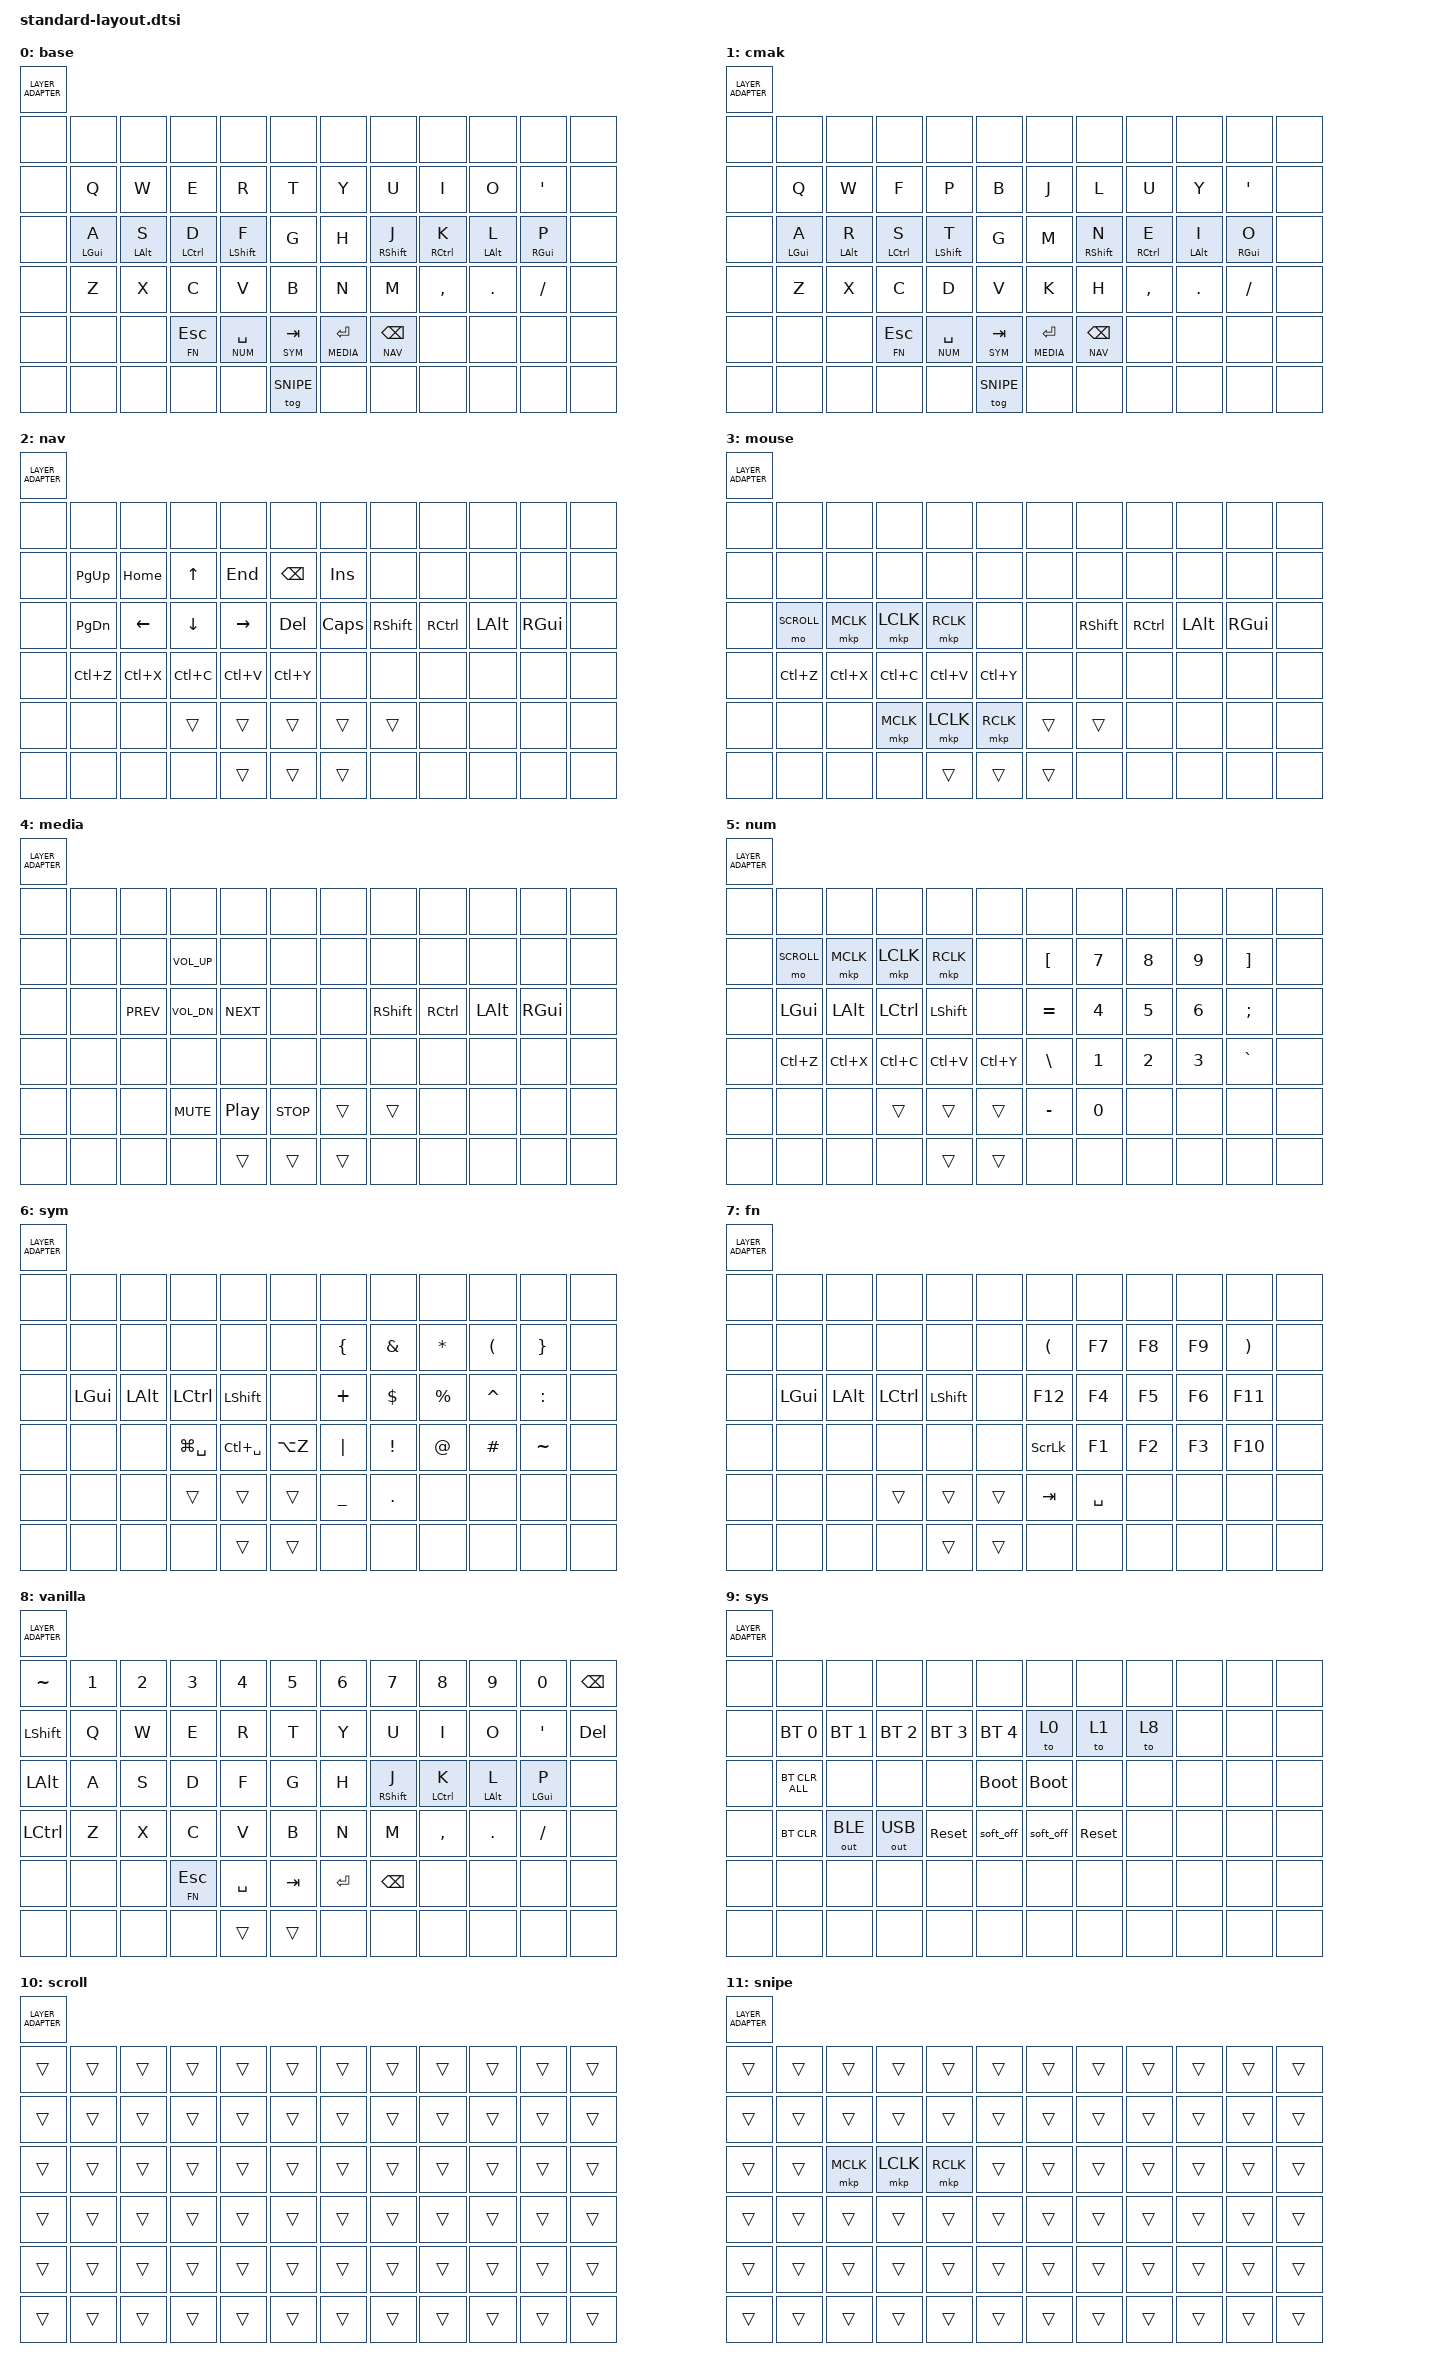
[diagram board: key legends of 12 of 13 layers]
#include <behaviors.dtsi>
#include <dt-bindings/zmk/bt.h>
#include <dt-bindings/zmk/outputs.h>
#include <dt-bindings/zmk/ext_power.h>
#include <dt-bindings/zmk/keys.h>

#define BASE    0
#define CMAK    1
#define NAV     2
#define MOUSE   3
#define MEDIA   4
#define NUM     5
#define SYM     6
#define FN      7
#define VANILLA 8
#define SYS     9
#define SCROLL  10
#define SNIPE   11
#define AUTOM   12
#define XXX     &none
#define ___     &trans

&lt {
    quick-tap-ms = <200>;
};

&caps_word {
    continue-list = <UNDERSCORE MINUS BSPC>;
};

/ {
    conditional_layers {
        compatible = "zmk,conditional-layers";
        tri_layer_right {
            if-layers = <MEDIA NAV>;
            then-layer = <SYS>;
        };
        tri_layer_left {
            if-layers = <SYM NUM>;
            then-layer = <SYS>;
        };
        tri_layer_scroll {
            if-layers = <NUM FN>;
            then-layer = <SCROLL>;
        };
    };
};

/ {
    behaviors {
        hm: homerow_mods {
            compatible = "zmk,behavior-hold-tap";
            #binding-cells = <2>;
            flavor = "tap-preferred";
            tapping-term-ms = <200>;
            quick-tap-ms = <200>;
            bindings = <&kp>, <&kp>;
        };
        mlt: mouse_layer_tap {
            compatible = "zmk,behavior-hold-tap";
            #binding-cells = <2>;
            tapping-term-ms = <200>;
            quick-tap-ms = <200>;
            flavor = "tap-preferred";
            bindings = <&mo>, <&mkp>;
        };
        lpar_ht: lpar_hold_tap {
            compatible = "zmk,behavior-hold-tap";
            #binding-cells = <2>;
            flavor = "tap-preferred";
            tapping-term-ms = <200>;
            quick-tap-ms = <200>;
            bindings = <&lpar_hold_macro>, <&kp>;
        };
        rpar_ht: rpar_hold_tap {
            compatible = "zmk,behavior-hold-tap";
            #binding-cells = <2>;
            flavor = "tap-preferred";
            tapping-term-ms = <200>;
            quick-tap-ms = <200>;
            bindings = <&rpar_hold_macro>, <&kp>;
        };
        lpar_hold_macro: lpar_hold_macro {
            compatible = "zmk,behavior-macro";
            #binding-cells = <0>;
            bindings = <&macro_press &kp LSHFT &kp LCTRL>,
                        <&macro_pause_for_release>,
                        <&macro_release &kp LSHFT &kp LCTRL>;
        };
        rpar_hold_macro: rpar_hold_macro {
            compatible = "zmk,behavior-macro";
            #binding-cells = <0>;
            bindings = <&macro_press &kp LCTRL &kp LALT>,
                        <&macro_pause_for_release>,
                        <&macro_release &kp LCTRL &kp LALT>;
        };
        tog_sys: toggle_sys_macro {
            compatible = "zmk,behavior-macro";
            #binding-cells = <0>;
            bindings = <&kp S &kp Y &kp S &kp SPACE &kp L &kp A &kp Y &kp E &kp R>,
                        <&tog SYS>;
        };
    };
};

/ {
    combos {
        compatible = "zmk,combos";
        combo_caps_word {
            timeout-ms = <50>;
            require-prior-idle-ms = <150>;
            key-positions = <LM1 RM1>;
            bindings = <&caps_word>;
        };
        combo_bspc {
            timeout-ms = <50>;
            require-prior-idle-ms = <150>;
            layers = <BASE CMAK>;
            key-positions = <RT1 RT2>;
            bindings = <&kp BSPC>;
        };
        combo_del {
            timeout-ms = <50>;
            require-prior-idle-ms = <150>;
            layers = <BASE CMAK>;
            key-positions = <RT2 RT3>;
            bindings = <&kp DEL>;
        };
        combo_lpar {
            timeout-ms = <50>;
            require-prior-idle-ms = <150>;
            layers = <BASE CMAK>;
            key-positions = <RM1 RM2>;
            bindings = <&lpar_ht 0 LPAR>;
        };
        combo_rpar {
            timeout-ms = <50>;
            require-prior-idle-ms = <150>;
            layers = <BASE CMAK>;
            key-positions = <RM2 RM3>;
            bindings = <&rpar_ht 0 RPAR>;
        };
        combo_lessthan {
            timeout-ms = <50>;
            require-prior-idle-ms = <150>;
            layers = <NUM>;
            key-positions = <RM1 RM2>;
            bindings = <&kp LT>;
        };
        combo_greaterthan {
            timeout-ms = <50>;
            require-prior-idle-ms = <150>;
            layers = <NUM>;
            key-positions = <RM2 RM3>;
            bindings = <&kp GT>;
        };
        combo_lbkt {
            timeout-ms = <50>;
            require-prior-idle-ms = <150>;
            layers = <BASE CMAK>;
            key-positions = <RB1 RB2>;
            bindings = <&kp LBKT>;
        };
        combo_rbkt {
            timeout-ms = <50>;
            require-prior-idle-ms = <150>;
            layers = <BASE CMAK>;
            key-positions = <RB2 RB3>;
            bindings = <&kp RBKT>;
        };
        combo_lbrc {
            timeout-ms = <50>;
            require-prior-idle-ms = <150>;
            layers = <NUM>;
            key-positions = <RB1 RB2>;
            bindings = <&kp LBRC>;
        };
        combo_rbrc {
            timeout-ms = <50>;
            require-prior-idle-ms = <150>;
            layers = <NUM>;
            key-positions = <RB2 RB3>;
            bindings = <&kp RBRC>;
        };
    };
};

// Keyboard Layout definition
// -----------------------------------------------------------------------------
// Not all keys defined here are used in all keyboards this layout suppots. To
// check where a key defined here is located on the physical layout of a
// keyboard, look in the keyboard's '.keymap' file.
/ {
    keymap {
        compatible = "zmk,keymap";

        base {
            bindings = <LAYER_ADAPTER(
XXX,            XXX,            XXX,            XXX,            XXX,            XXX,                    XXX,            XXX,            XXX,            XXX,            XXX,            XXX,
XXX,            &kp Q,          &kp W,          &kp E,          &kp R,          &kp T,                  &kp Y,          &kp U,          &kp I,          &kp O,          &kp SQT,        XXX,
XXX,            &hm LGUI A,     &hm LALT S,     &hm LCTRL D,    &hm LSHFT F,    &kp G,                  &kp H,          &hm RSHFT J,    &hm RCTRL K,    &hm LALT L,     &hm RGUI P,     XXX,
XXX,            &kp Z,          &kp X,          &kp C,          &kp V,          &kp B,                  &kp N,          &kp M,          &kp COMMA,      &kp DOT,        &kp FSLH,       XXX,
XXX,            XXX,            XXX,            &lt FN ESC,     &lt NUM SPACE,  &lt SYM TAB,            &lt MEDIA RET,  &lt NAV BSPC,   XXX,            XXX,            XXX,            XXX,
XXX,            XXX,            XXX,            XXX,            XXX,            &tog SNIPE,             XXX,            XXX,            XXX,            XXX,            XXX,            XXX
            )>;
        };

        cmak {
            bindings = <LAYER_ADAPTER(
XXX,            XXX,            XXX,            XXX,            XXX,            XXX,                    XXX,            XXX,            XXX,            XXX,            XXX,            XXX,
XXX,            &kp Q,          &kp W,          &kp F,          &kp P,          &kp B,                  &kp J,          &kp L,          &kp U,          &kp Y,          &kp SQT,        XXX,
XXX,            &hm LGUI A,     &hm LALT R,     &hm LCTRL S,    &hm LSHFT T,    &kp G,                  &kp M,          &hm RSHFT N,    &hm RCTRL E,    &hm LALT I,     &hm RGUI O,     XXX,
XXX,            &kp Z,          &kp X,          &kp C,          &kp D,          &kp V,                  &kp K,          &kp H,          &kp COMMA,      &kp DOT,        &kp FSLH,       XXX,
XXX,            XXX,            XXX,            &lt FN ESC,     &lt NUM SPACE,  &lt SYM TAB,            &lt MEDIA RET,  &lt NAV BSPC,   XXX,            XXX,            XXX,            XXX,
XXX,            XXX,            XXX,            XXX,            XXX,            &tog SNIPE,             XXX,            XXX,            XXX,            XXX,            XXX,            XXX
            )>;
        };

        nav {
            bindings = <LAYER_ADAPTER(
XXX,            XXX,            XXX,            XXX,            XXX,            XXX,                    XXX,            XXX,            XXX,            XXX,            XXX,            XXX,
XXX,            &kp PG_UP,      &kp HOME,       &kp UP,         &kp END,        &kp BSPC,               &kp INS,        XXX,            XXX,            XXX,            XXX,            XXX,
XXX,            &kp PG_DN,      &kp LEFT,       &kp DOWN,       &kp RIGHT,      &kp DEL,                &kp CAPS,       &kp RSHFT,      &kp RCTRL,      &kp LALT,       &kp RGUI,       XXX,
XXX,            &kp LC(Z),      &kp LC(X),      &kp LC(C),      &kp LC(V),      &kp LC(Y),              XXX,            XXX,            XXX,            XXX,            XXX,            XXX,
XXX,            XXX,            XXX,            ___,            ___,            ___,                    ___,            ___,            XXX,            XXX,            XXX,            XXX,
XXX,            XXX,            XXX,            XXX,            ___,            ___,                    ___,            XXX,            XXX,            XXX,            XXX,            XXX
            )>;
        };

        mouse {
            bindings = <LAYER_ADAPTER(
XXX,            XXX,            XXX,            XXX,            XXX,            XXX,                    XXX,            XXX,            XXX,            XXX,            XXX,            XXX,
XXX,            XXX,            XXX,            XXX,            XXX,            XXX,                    XXX,            XXX,            XXX,            XXX,            XXX,            XXX,
XXX,            &mo SCROLL,     &mkp MCLK,      &mkp LCLK,      &mkp RCLK,      XXX,                    XXX,            &kp RSHFT,      &kp RCTRL,      &kp LALT,       &kp RGUI,       XXX,
XXX,            &kp LC(Z),      &kp LC(X),      &kp LC(C),      &kp LC(V),      &kp LC(Y),              XXX,            XXX,            XXX,            XXX,            XXX,            XXX,
XXX,            XXX,            XXX,            &mkp MCLK,      &mkp LCLK,      &mkp RCLK,              ___,            ___,            XXX,            XXX,            XXX,            XXX,
XXX,            XXX,            XXX,            XXX,            ___,            ___,                    ___,            XXX,            XXX,            XXX,            XXX,            XXX
            )>;
        };

        media {
            bindings = <LAYER_ADAPTER(
XXX,            XXX,            XXX,            XXX,            XXX,            XXX,                    XXX,            XXX,            XXX,            XXX,            XXX,            XXX,
XXX,            XXX,            XXX,            &kp C_VOL_UP,   XXX,            XXX,                    XXX,            XXX,            XXX,            XXX,            XXX,            XXX,
XXX,            XXX,            &kp C_PREV,     &kp C_VOL_DN,   &kp C_NEXT,     XXX,                    XXX,            &kp RSHFT,      &kp RCTRL,      &kp LALT,       &kp RGUI,       XXX,
XXX,            XXX,            XXX,            XXX,            XXX,            XXX,                    XXX,            XXX,            XXX,            XXX,            XXX,            XXX,
XXX,            XXX,            XXX,            &kp C_MUTE,     &kp C_PP,       &kp C_STOP,             ___,            ___,            XXX,            XXX,            XXX,            XXX,
XXX,            XXX,            XXX,            XXX,            ___,            ___,                    ___,            XXX,            XXX,            XXX,            XXX,            XXX
            )>;
        };

        num {
            bindings = <LAYER_ADAPTER(
XXX,            XXX,            XXX,            XXX,            XXX,            XXX,                    XXX,           XXX,            XXX,            XXX,            XXX,           XXX,
XXX,            &mo SCROLL,     &mkp MCLK,      &mkp LCLK,      &mkp RCLK,      XXX,                    &kp LBKT,      &kp N7,         &kp N8,         &kp N9,         &kp RBKT,      XXX,
XXX,            &kp LGUI,       &kp LALT,       &kp LCTRL,      &kp LSHFT,      XXX,                    &kp EQUAL,     &kp N4,         &kp N5,         &kp N6,         &kp SEMI,      XXX,
XXX,            &kp LC(Z),      &kp LC(X),      &kp LC(C),      &kp LC(V),      &kp LC(Y),              &kp BSLH,      &kp N1,         &kp N2,         &kp N3,         &kp GRAVE,     XXX,
XXX,            XXX,            XXX,            ___,            ___,            ___,                    &kp MINUS,     &kp N0,         XXX,            XXX,            XXX,           XXX,
XXX,            XXX,            XXX,            XXX,            ___,            ___,                    XXX,           XXX,            XXX,            XXX,            XXX,           XXX
            )>;
        };

        sym {
            bindings = <LAYER_ADAPTER(
XXX,            XXX,            XXX,            XXX,            XXX,            XXX,                    XXX,            XXX,            XXX,            XXX,            XXX,            XXX,
XXX,            XXX,            XXX,            XXX,            XXX,            XXX,                    &kp LBRC,       &kp AMPS,       &kp ASTRK,      &kp LPAR,       &kp RBRC,       XXX,
XXX,            &kp LGUI,       &kp LALT,       &kp LCTRL,      &kp LSHFT,      XXX,                    &kp PLUS,       &kp DLLR,       &kp PRCNT,      &kp CARET,      &kp COLON,      XXX,
XXX,            XXX,            XXX,            &kp LG(SPACE),  &kp LC(SPACE),  &kp LA(Z),              &kp PIPE,       &kp EXCL,       &kp AT,         &kp HASH,       &kp TILDE,      XXX,
XXX,            XXX,            XXX,            ___,            ___,            ___,                    &kp UNDER,      &kp DOT,        XXX,            XXX,            XXX,            XXX,
XXX,            XXX,            XXX,            XXX,            ___,            ___,                    XXX,            XXX,            XXX,            XXX,            XXX,            XXX
            )>;
        };

        fn {
            bindings = <LAYER_ADAPTER(
XXX,             XXX,            XXX,            XXX,            XXX,           XXX,                    XXX,            XXX,            XXX,            XXX,            XXX,            XXX,
XXX,             XXX,            XXX,            XXX,            XXX,           XXX,                    &kp LPAR,       &kp F7,         &kp F8,         &kp F9,         &kp RPAR,       XXX,
XXX,             &kp LGUI,       &kp LALT,       &kp LCTRL,      &kp LSHFT,     XXX,                    &kp F12,        &kp F4,         &kp F5,         &kp F6,         &kp F11,        XXX,
XXX,             XXX,            XXX,            XXX,            XXX,           XXX,                    &kp SLCK,       &kp F1,         &kp F2,         &kp F3,         &kp F10,        XXX,
XXX,             XXX,            XXX,            ___,            ___,           ___,                    &kp TAB,        &kp SPACE,      XXX,            XXX,            XXX,            XXX,
XXX,             XXX,            XXX,            XXX,            ___,           ___,                    XXX,            XXX,            XXX,            XXX,            XXX,            XXX
            )>;
        };

        vanilla {
            bindings = <LAYER_ADAPTER(
&kp TILDE,      &kp 1,          &kp 2,          &kp 3,          &kp 4,          &kp 5,                  &kp 6,          &kp 7,          &kp 8,          &kp 9,          &kp 0,          &kp BSPC,
&kp LSHFT,      &kp Q,          &kp W,          &kp E,          &kp R,          &kp T,                  &kp Y,          &kp U,          &kp I,          &kp O,          &kp SQT,        &kp DEL,
&kp LALT,       &kp A,          &kp S,          &kp D,          &kp F,          &kp G,                  &kp H,          &hm RSHIFT J,   &hm LCTRL K,    &hm LALT L,     &hm LGUI P,     XXX,
&kp LCTRL,      &kp Z,          &kp X,          &kp C,          &kp V,          &kp B,                  &kp N,          &kp M,          &kp COMMA,      &kp DOT,        &kp FSLH,       XXX,
XXX,            XXX,            XXX,            &lt FN ESC,     &kp SPACE,      &kp TAB,                &kp RET,        &kp BSPC,       XXX,            XXX,            XXX,            XXX,
XXX,            XXX,            XXX,            XXX,            ___,            ___,                    XXX,            XXX,            XXX,            XXX,            XXX,            XXX
            )>;
        };

        sys {
            bindings = <LAYER_ADAPTER(
XXX,            XXX,            XXX,            XXX,            XXX,            XXX,                    XXX,            XXX,            XXX,            XXX,            XXX,            XXX,
XXX,            &bt BT_SEL 0,   &bt BT_SEL 1,   &bt BT_SEL 2,   &bt BT_SEL 3,   &bt BT_SEL 4,           &to 0,          &to 1,          &to 8,          XXX,            XXX,            XXX,
XXX,            &bt BT_CLR_ALL, XXX,            XXX,            XXX,            &bootloader,            &bootloader,    XXX,            XXX,            XXX,            XXX,            XXX,
XXX,            &bt BT_CLR,     &out OUT_BLE,   &out OUT_USB,   &sys_reset,     &soft_off,              &soft_off,      &sys_reset,     XXX,            XXX,            XXX,            XXX,
XXX,            XXX,            XXX,            XXX,            XXX,            XXX,                    XXX,            XXX,            XXX,            XXX,            XXX,            XXX,
XXX,            XXX,            XXX,            XXX,            XXX,            XXX,                    XXX,            XXX,            XXX,            XXX,            XXX,            XXX
            )>;
        };

        scroll {
            bindings = <LAYER_ADAPTER(
___,            ___,            ___,            ___,            ___,            ___,                    ___,            ___,            ___,            ___,            ___,            ___,
___,            ___,            ___,            ___,            ___,            ___,                    ___,            ___,            ___,            ___,            ___,            ___,
___,            ___,            ___,            ___,            ___,            ___,                    ___,            ___,            ___,            ___,            ___,            ___,
___,            ___,            ___,            ___,            ___,            ___,                    ___,            ___,            ___,            ___,            ___,            ___,
___,            ___,            ___,            ___,            ___,            ___,                    ___,            ___,            ___,            ___,            ___,            ___,
___,            ___,            ___,            ___,            ___,            ___,                    ___,            ___,            ___,            ___,            ___,            ___
            )>;
        };

        snipe {
            bindings = <LAYER_ADAPTER(
___,            ___,            ___,            ___,            ___,            ___,                    ___,            ___,            ___,            ___,            ___,            ___,
___,            ___,            ___,            ___,            ___,            ___,                    ___,            ___,            ___,            ___,            ___,            ___,
___,            ___,            &mkp MCLK,      &mkp LCLK,      &mkp RCLK,      ___,                    ___,            ___,            ___,            ___,            ___,            ___,
___,            ___,            ___,            ___,            ___,            ___,                    ___,            ___,            ___,            ___,            ___,            ___,
___,            ___,            ___,            ___,            ___,            ___,                    ___,            ___,            ___,            ___,            ___,            ___,
___,            ___,            ___,            ___,            ___,            ___,                    ___,            ___,            ___,            ___,            ___,            ___
            )>;
        };

        automouse {
            bindings = <LAYER_ADAPTER(
___,            ___,            ___,            ___,            ___,            ___,                    ___,            ___,            ___,            ___,            ___,            ___,
___,            ___,            ___,            ___,            ___,            ___,                    ___,            ___,            ___,            ___,            ___,            ___,
___,            ___,            &mkp MCLK,      &mkp LCLK,      &mkp RCLK,      ___,                    ___,            ___,            ___,            ___,            ___,            ___,
___,            ___,            ___,            ___,            ___,            ___,                    ___,            ___,            ___,            ___,            ___,            ___,
___,            ___,            ___,            ___,            ___,            ___,                    ___,            ___,            ___,            ___,            ___,            ___,
___,            ___,            ___,            ___,            ___,            ___,                    ___,            ___,            ___,            ___,            ___,            ___
            )>;
        };
    };
};
